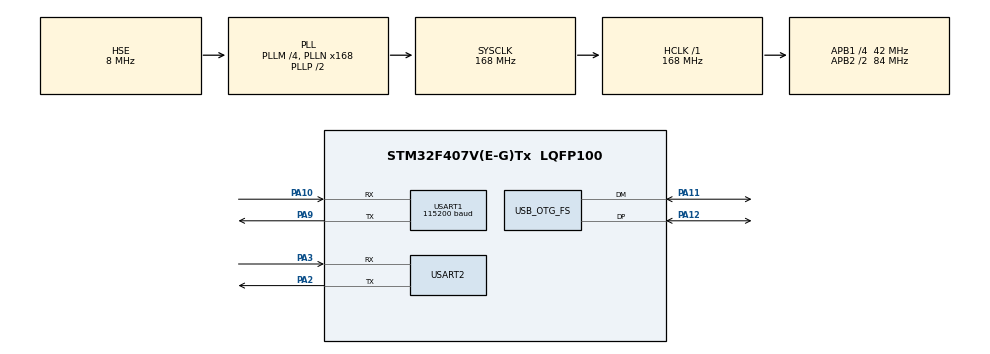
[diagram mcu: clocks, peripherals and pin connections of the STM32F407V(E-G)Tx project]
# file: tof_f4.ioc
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Mcu.Family=STM32F4
Mcu.Name=STM32F407V(E-G)Tx
Mcu.Package=LQFP100
NVIC.OTG_FS_IRQn=true\:0\:0\:false\:false\:true\:false\:true\:true
NVIC.PriorityGroup=NVIC_PRIORITYGROUP_4
PA10.Mode=Asynchronous
PA10.Signal=USART1_RX
PA11.Mode=Device_Only
PA11.Signal=USB_OTG_FS_DM
PA12.Mode=Device_Only
PA12.Signal=USB_OTG_FS_DP
PA2.Mode=Asynchronous
PA2.Signal=USART2_TX
PA3.Mode=Asynchronous
PA3.Signal=USART2_RX
PA9.Mode=Asynchronous
PA9.Signal=USART1_TX
PH0-OSC_IN.Mode=HSE-External-Oscillator
PH0-OSC_IN.Signal=RCC_OSC_IN
PH1-OSC_OUT.Mode=HSE-External-Oscillator
PH1-OSC_OUT.Signal=RCC_OSC_OUT
ProjectManager.HeapSize=0x200
ProjectManager.StackSize=0x400
ProjectManager.TargetToolchain=STM32CubeIDE
RCC.48MHZClocksFreq_Value=48000000
RCC.AHBFreq_Value=168000000
RCC.APB1CLKDivider=RCC_HCLK_DIV4
RCC.APB1Freq_Value=42000000
RCC.APB1TimFreq_Value=84000000
RCC.APB2CLKDivider=RCC_HCLK_DIV2
RCC.APB2Freq_Value=84000000
RCC.APB2TimFreq_Value=168000000
RCC.CortexFreq_Value=168000000
RCC.HCLKFreq_Value=168000000
RCC.HSE_VALUE=8000000
RCC.HSI_VALUE=16000000
RCC.LSE_VALUE=32768
RCC.PLLM=4
RCC.PLLN=168
RCC.PLLQ=7
RCC.SYSCLKFreq_VALUE=168000000
RCC.SYSCLKSource=RCC_SYSCLKSOURCE_PLLCLK
RCC.VCOOutputFreq_Value=336000000
USART1.BaudRate=115200
USART1.VirtualMode=VM_ASYNC
USART2.VirtualMode=VM_ASYNC
USB_DEVICE.CLASS_NAME_FS=CDC
USB_DEVICE.VirtualMode-CDC_FS=Cdc
USB_DEVICE.VirtualModeFS=Cdc_FS
USB_OTG_FS.VirtualMode=Device_Only
VP_USB_DEVICE_VS_USB_DEVICE_CDC_FS.Mode=CDC_FS
board=custom

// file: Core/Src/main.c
/* USER CODE BEGIN Header */
/**
  ******************************************************************************
  * @file           : main.c
  * @brief          : Main program body
  ******************************************************************************
  * @attention
  *
  * Copyright (c) 2026 STMicroelectronics.
  * All rights reserved.
  *
  * This software is licensed under terms that can be found in the LICENSE file
  * in the root directory of this software component.
  * If no LICENSE file comes with this software, it is provided AS-IS.
  *
  ******************************************************************************
  */
/* USER CODE END Header */
#include "main.h"
#include "usb_device.h"
#include "usbd_cdc_if.h"
#include <stdio.h>

/* USER CODE BEGIN PM */
/* Private variables ---------------------------------------------------------*/
UART_HandleTypeDef huart1; // TOF Sensor
UART_HandleTypeDef huart2; // PC Console

/* --- TOF Sensor Variables --- */
uint8_t rx_byte;
uint8_t tof_buffer[16];
uint32_t distance_mm = 0;
/* USER CODE END PM */

UART_HandleTypeDef huart1;
UART_HandleTypeDef huart2;

void SystemClock_Config(void);
static void MX_GPIO_Init(void);
static void MX_USART1_UART_Init(void);
static void MX_USART2_UART_Init(void);
/* USER CODE BEGIN PFP */
// Make sure this is included

int __io_putchar(int ch) {
    uint8_t c = (uint8_t)ch;
    // Send to USB Virtual COM Port
    CDC_Transmit_FS(&c, 1);

    // Also keep sending to UART2 (Optional, just in case)
    HAL_UART_Transmit(&huart2, &c, 1, 10);
    return ch;
}
/* USER CODE END PFP */

int main(void)
{

  /* MCU Configuration--------------------------------------------------------*/

  /* Reset of all peripherals, Initializes the Flash interface and the Systick. */
  HAL_Init();

  /* Configure the system clock */
  SystemClock_Config();

  /* Initialize all configured peripherals */
  MX_GPIO_Init();
  MX_USB_DEVICE_Init();
  MX_USART1_UART_Init();
  MX_USART2_UART_Init();
  /* USER CODE BEGIN 2 */
  //HAL_Delay(1000); // Wait for sensor to wake up

    // The magic "Change Baud to 115200" command for Waveshare TOF
  //uint8_t change_baud[] = {0x57, 0x10, 0x12, 0x00, 0x00, 0x01, 0x00, 0x00, 0x20, 0x01, 0x00, 0x00, 0x00, 0x00, 0x00, 0x9B};
  //HAL_UART_Transmit(&huart1, change_baud, 16, 100);
  //  HAL_Delay(500);

  /* USER CODE END 2 */

  /* Infinite loop */
  while (1)
  {
	  if (HAL_UART_Receive(&huart1, &rx_byte, 1, 10) == HAL_OK) {

	  	 	  	            if (rx_byte == 0x57) {
	  	 	  	                tof_buffer[0] = rx_byte;

	  	 	  	                // 2. We found the header! Immediately read the next 15 bytes
	  	 	  	                if (HAL_UART_Receive(&huart1, &tof_buffer[1], 15, 20) == HAL_OK) {

	  	 	  	                    // 3. Extract and calculate the distance (Bytes 8, 9, and 10)
	  	 	  	                    distance_mm = tof_buffer[8] | (tof_buffer[9] << 8) | (tof_buffer[10] << 16);

	  	 	  	                    // 4. Print the result!
	  	 	  	                    printf("Distance: %lu mm\r\n", distance_mm);
	  	 	  	                }
	  	 	  	            }
	  	 	  	        }
  }
}

void SystemClock_Config(void)
{
  RCC_OscInitTypeDef RCC_OscInitStruct = {0};
  RCC_ClkInitTypeDef RCC_ClkInitStruct = {0};

  /** Configure the main internal regulator output voltage
  */
  __HAL_RCC_PWR_CLK_ENABLE();
  __HAL_PWR_VOLTAGESCALING_CONFIG(PWR_REGULATOR_VOLTAGE_SCALE1);

  /** Initializes the RCC Oscillators according to the specified parameters
  * in the RCC_OscInitTypeDef structure.
  */
  RCC_OscInitStruct.OscillatorType = RCC_OSCILLATORTYPE_HSE;
  RCC_OscInitStruct.HSEState = RCC_HSE_ON;
  RCC_OscInitStruct.PLL.PLLState = RCC_PLL_ON;
  RCC_OscInitStruct.PLL.PLLSource = RCC_PLLSOURCE_HSE;
  RCC_OscInitStruct.PLL.PLLM = 4;
  RCC_OscInitStruct.PLL.PLLN = 168;
  RCC_OscInitStruct.PLL.PLLP = RCC_PLLP_DIV2;
  RCC_OscInitStruct.PLL.PLLQ = 7;
  if (HAL_RCC_OscConfig(&RCC_OscInitStruct) != HAL_OK)
  {
    Error_Handler();
  }

  /** Initializes the CPU, AHB and APB buses clocks
  */
  RCC_ClkInitStruct.ClockType = RCC_CLOCKTYPE_HCLK|RCC_CLOCKTYPE_SYSCLK
                              |RCC_CLOCKTYPE_PCLK1|RCC_CLOCKTYPE_PCLK2;
  RCC_ClkInitStruct.SYSCLKSource = RCC_SYSCLKSOURCE_PLLCLK;
  RCC_ClkInitStruct.AHBCLKDivider = RCC_SYSCLK_DIV1;
  RCC_ClkInitStruct.APB1CLKDivider = RCC_HCLK_DIV4;
  RCC_ClkInitStruct.APB2CLKDivider = RCC_HCLK_DIV2;

  if (HAL_RCC_ClockConfig(&RCC_ClkInitStruct, FLASH_LATENCY_5) != HAL_OK)
  {
    Error_Handler();
  }
}

static void MX_USART1_UART_Init(void)
{

  huart1.Instance = USART1;
  huart1.Init.BaudRate = 115200;
  huart1.Init.WordLength = UART_WORDLENGTH_8B;
  huart1.Init.StopBits = UART_STOPBITS_1;
  huart1.Init.Parity = UART_PARITY_NONE;
  huart1.Init.Mode = UART_MODE_TX_RX;
  huart1.Init.HwFlowCtl = UART_HWCONTROL_NONE;
  huart1.Init.OverSampling = UART_OVERSAMPLING_16;
  if (HAL_UART_Init(&huart1) != HAL_OK)
  {
    Error_Handler();
  }

}

static void MX_USART2_UART_Init(void)
{

  huart2.Instance = USART2;
  huart2.Init.BaudRate = 115200;
  huart2.Init.WordLength = UART_WORDLENGTH_8B;
  huart2.Init.StopBits = UART_STOPBITS_1;
  huart2.Init.Parity = UART_PARITY_NONE;
  huart2.Init.Mode = UART_MODE_TX_RX;
  huart2.Init.HwFlowCtl = UART_HWCONTROL_NONE;
  huart2.Init.OverSampling = UART_OVERSAMPLING_16;
  if (HAL_UART_Init(&huart2) != HAL_OK)
  {
    Error_Handler();
  }

}

static void MX_GPIO_Init(void)
{

  /* GPIO Ports Clock Enable */
  __HAL_RCC_GPIOH_CLK_ENABLE();
  __HAL_RCC_GPIOA_CLK_ENABLE();

}

void Error_Handler(void)
{
  __disable_irq();
  while (1)
  {
  }
}
